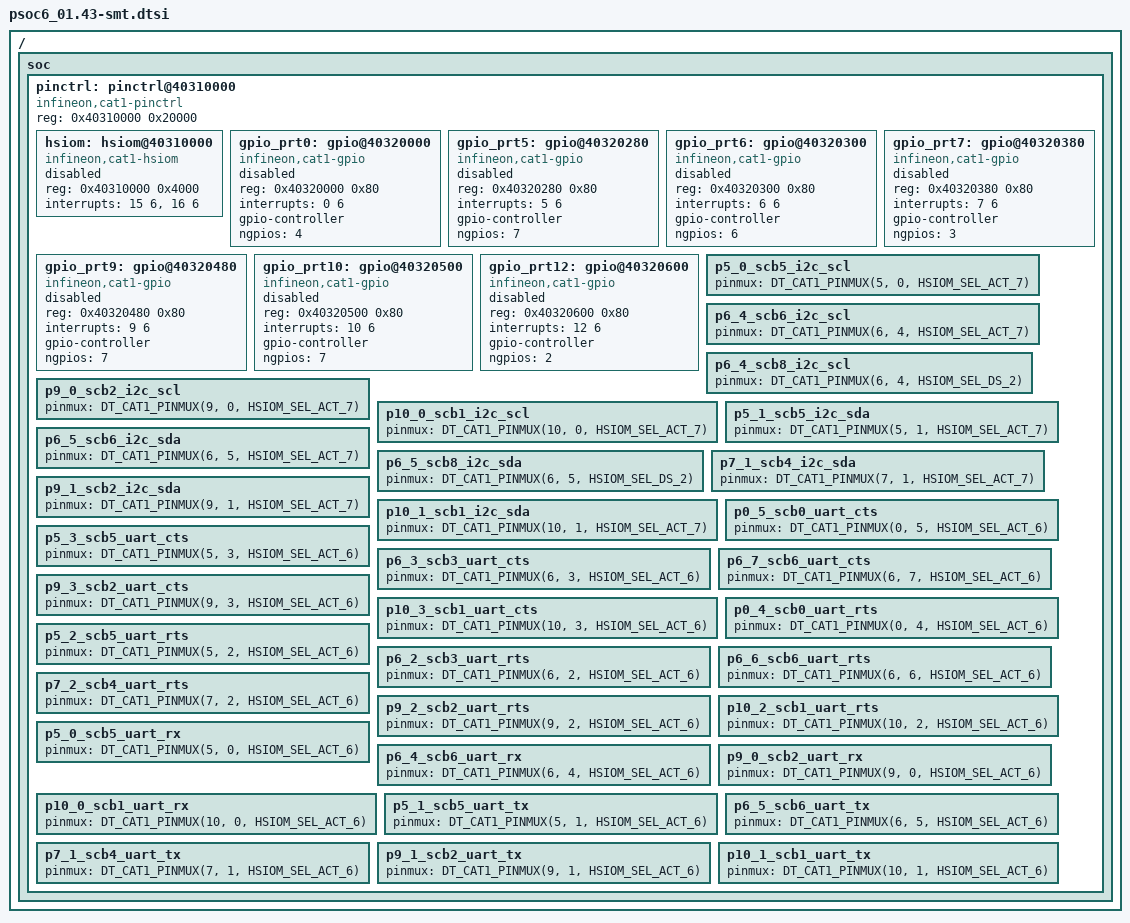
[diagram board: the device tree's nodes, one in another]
/*
 * Copyright (c) 2022 Cypress Semiconductor Corporation (an Infineon company) or
 * an affiliate of Cypress Semiconductor Corporation
 *
 * SPDX-License-Identifier: Apache-2.0
 */

#include <zephyr/dt-bindings/gpio/gpio.h>
#include <zephyr/dt-bindings/pinctrl/ifx_cat1-pinctrl.h>
#include "psoc6_01.dtsi"

/ {
	soc {
		pinctrl: pinctrl@40310000 {
			compatible = "infineon,cat1-pinctrl";
			reg = <0x40310000 0x20000>;
			#address-cells = <1>;
			#size-cells = <0>;

			hsiom: hsiom@40310000 {
				compatible = "infineon,cat1-hsiom";
				reg = <0x40310000 0x4000>;
				interrupts = <15 6>, <16 6>;
				status = "disabled";
			};

			gpio_prt0: gpio@40320000 {
				compatible = "infineon,cat1-gpio";
				reg = <0x40320000 0x80>;
				interrupts = <0 6>;
				gpio-controller;
				ngpios = <4>;
				status = "disabled";
				#gpio-cells = <2>;
			};
			gpio_prt5: gpio@40320280 {
				compatible = "infineon,cat1-gpio";
				reg = <0x40320280 0x80>;
				interrupts = <5 6>;
				gpio-controller;
				ngpios = <7>;
				status = "disabled";
				#gpio-cells = <2>;
			};
			gpio_prt6: gpio@40320300 {
				compatible = "infineon,cat1-gpio";
				reg = <0x40320300 0x80>;
				interrupts = <6 6>;
				gpio-controller;
				ngpios = <6>;
				status = "disabled";
				#gpio-cells = <2>;
			};
			gpio_prt7: gpio@40320380 {
				compatible = "infineon,cat1-gpio";
				reg = <0x40320380 0x80>;
				interrupts = <7 6>;
				gpio-controller;
				ngpios = <3>;
				status = "disabled";
				#gpio-cells = <2>;
			};
			gpio_prt9: gpio@40320480 {
				compatible = "infineon,cat1-gpio";
				reg = <0x40320480 0x80>;
				interrupts = <9 6>;
				gpio-controller;
				ngpios = <7>;
				status = "disabled";
				#gpio-cells = <2>;
			};
			gpio_prt10: gpio@40320500 {
				compatible = "infineon,cat1-gpio";
				reg = <0x40320500 0x80>;
				interrupts = <10 6>;
				gpio-controller;
				ngpios = <7>;
				status = "disabled";
				#gpio-cells = <2>;
			};
			gpio_prt12: gpio@40320600 {
				compatible = "infineon,cat1-gpio";
				reg = <0x40320600 0x80>;
				interrupts = <12 6>;
				gpio-controller;
				ngpios = <2>;
				status = "disabled";
				#gpio-cells = <2>;
			};

			/* scb_i2c_scl */
			/omit-if-no-ref/ p5_0_scb5_i2c_scl: p5_0_scb5_i2c_scl {
				pinmux = <DT_CAT1_PINMUX(5, 0, HSIOM_SEL_ACT_7)>;
			};
			/omit-if-no-ref/ p6_4_scb6_i2c_scl: p6_4_scb6_i2c_scl {
				pinmux = <DT_CAT1_PINMUX(6, 4, HSIOM_SEL_ACT_7)>;
			};
			/omit-if-no-ref/ p6_4_scb8_i2c_scl: p6_4_scb8_i2c_scl {
				pinmux = <DT_CAT1_PINMUX(6, 4, HSIOM_SEL_DS_2)>;
			};
			/omit-if-no-ref/ p9_0_scb2_i2c_scl: p9_0_scb2_i2c_scl {
				pinmux = <DT_CAT1_PINMUX(9, 0, HSIOM_SEL_ACT_7)>;
			};
			/omit-if-no-ref/ p10_0_scb1_i2c_scl: p10_0_scb1_i2c_scl {
				pinmux = <DT_CAT1_PINMUX(10, 0, HSIOM_SEL_ACT_7)>;
			};

			/* scb_i2c_sda */
			/omit-if-no-ref/ p5_1_scb5_i2c_sda: p5_1_scb5_i2c_sda {
				pinmux = <DT_CAT1_PINMUX(5, 1, HSIOM_SEL_ACT_7)>;
			};
			/omit-if-no-ref/ p6_5_scb6_i2c_sda: p6_5_scb6_i2c_sda {
				pinmux = <DT_CAT1_PINMUX(6, 5, HSIOM_SEL_ACT_7)>;
			};
			/omit-if-no-ref/ p6_5_scb8_i2c_sda: p6_5_scb8_i2c_sda {
				pinmux = <DT_CAT1_PINMUX(6, 5, HSIOM_SEL_DS_2)>;
			};
			/omit-if-no-ref/ p7_1_scb4_i2c_sda: p7_1_scb4_i2c_sda {
				pinmux = <DT_CAT1_PINMUX(7, 1, HSIOM_SEL_ACT_7)>;
			};
			/omit-if-no-ref/ p9_1_scb2_i2c_sda: p9_1_scb2_i2c_sda {
				pinmux = <DT_CAT1_PINMUX(9, 1, HSIOM_SEL_ACT_7)>;
			};
			/omit-if-no-ref/ p10_1_scb1_i2c_sda: p10_1_scb1_i2c_sda {
				pinmux = <DT_CAT1_PINMUX(10, 1, HSIOM_SEL_ACT_7)>;
			};

			/* scb_uart_cts */
			/omit-if-no-ref/ p0_5_scb0_uart_cts: p0_5_scb0_uart_cts {
				pinmux = <DT_CAT1_PINMUX(0, 5, HSIOM_SEL_ACT_6)>;
			};
			/omit-if-no-ref/ p5_3_scb5_uart_cts: p5_3_scb5_uart_cts {
				pinmux = <DT_CAT1_PINMUX(5, 3, HSIOM_SEL_ACT_6)>;
			};
			/omit-if-no-ref/ p6_3_scb3_uart_cts: p6_3_scb3_uart_cts {
				pinmux = <DT_CAT1_PINMUX(6, 3, HSIOM_SEL_ACT_6)>;
			};
			/omit-if-no-ref/ p6_7_scb6_uart_cts: p6_7_scb6_uart_cts {
				pinmux = <DT_CAT1_PINMUX(6, 7, HSIOM_SEL_ACT_6)>;
			};
			/omit-if-no-ref/ p9_3_scb2_uart_cts: p9_3_scb2_uart_cts {
				pinmux = <DT_CAT1_PINMUX(9, 3, HSIOM_SEL_ACT_6)>;
			};
			/omit-if-no-ref/ p10_3_scb1_uart_cts: p10_3_scb1_uart_cts {
				pinmux = <DT_CAT1_PINMUX(10, 3, HSIOM_SEL_ACT_6)>;
			};

			/* scb_uart_rts */
			/omit-if-no-ref/ p0_4_scb0_uart_rts: p0_4_scb0_uart_rts {
				pinmux = <DT_CAT1_PINMUX(0, 4, HSIOM_SEL_ACT_6)>;
			};
			/omit-if-no-ref/ p5_2_scb5_uart_rts: p5_2_scb5_uart_rts {
				pinmux = <DT_CAT1_PINMUX(5, 2, HSIOM_SEL_ACT_6)>;
			};
			/omit-if-no-ref/ p6_2_scb3_uart_rts: p6_2_scb3_uart_rts {
				pinmux = <DT_CAT1_PINMUX(6, 2, HSIOM_SEL_ACT_6)>;
			};
			/omit-if-no-ref/ p6_6_scb6_uart_rts: p6_6_scb6_uart_rts {
				pinmux = <DT_CAT1_PINMUX(6, 6, HSIOM_SEL_ACT_6)>;
			};
			/omit-if-no-ref/ p7_2_scb4_uart_rts: p7_2_scb4_uart_rts {
				pinmux = <DT_CAT1_PINMUX(7, 2, HSIOM_SEL_ACT_6)>;
			};
			/omit-if-no-ref/ p9_2_scb2_uart_rts: p9_2_scb2_uart_rts {
				pinmux = <DT_CAT1_PINMUX(9, 2, HSIOM_SEL_ACT_6)>;
			};
			/omit-if-no-ref/ p10_2_scb1_uart_rts: p10_2_scb1_uart_rts {
				pinmux = <DT_CAT1_PINMUX(10, 2, HSIOM_SEL_ACT_6)>;
			};

			/* scb_uart_rx */
			/omit-if-no-ref/ p5_0_scb5_uart_rx: p5_0_scb5_uart_rx {
				pinmux = <DT_CAT1_PINMUX(5, 0, HSIOM_SEL_ACT_6)>;
			};
			/omit-if-no-ref/ p6_4_scb6_uart_rx: p6_4_scb6_uart_rx {
				pinmux = <DT_CAT1_PINMUX(6, 4, HSIOM_SEL_ACT_6)>;
			};
			/omit-if-no-ref/ p9_0_scb2_uart_rx: p9_0_scb2_uart_rx {
				pinmux = <DT_CAT1_PINMUX(9, 0, HSIOM_SEL_ACT_6)>;
			};
			/omit-if-no-ref/ p10_0_scb1_uart_rx: p10_0_scb1_uart_rx {
				pinmux = <DT_CAT1_PINMUX(10, 0, HSIOM_SEL_ACT_6)>;
			};

			/* scb_uart_tx */
			/omit-if-no-ref/ p5_1_scb5_uart_tx: p5_1_scb5_uart_tx {
				pinmux = <DT_CAT1_PINMUX(5, 1, HSIOM_SEL_ACT_6)>;
			};
			/omit-if-no-ref/ p6_5_scb6_uart_tx: p6_5_scb6_uart_tx {
				pinmux = <DT_CAT1_PINMUX(6, 5, HSIOM_SEL_ACT_6)>;
			};
			/omit-if-no-ref/ p7_1_scb4_uart_tx: p7_1_scb4_uart_tx {
				pinmux = <DT_CAT1_PINMUX(7, 1, HSIOM_SEL_ACT_6)>;
			};
			/omit-if-no-ref/ p9_1_scb2_uart_tx: p9_1_scb2_uart_tx {
				pinmux = <DT_CAT1_PINMUX(9, 1, HSIOM_SEL_ACT_6)>;
			};
			/omit-if-no-ref/ p10_1_scb1_uart_tx: p10_1_scb1_uart_tx {
				pinmux = <DT_CAT1_PINMUX(10, 1, HSIOM_SEL_ACT_6)>;
			};

		};
	};
};
